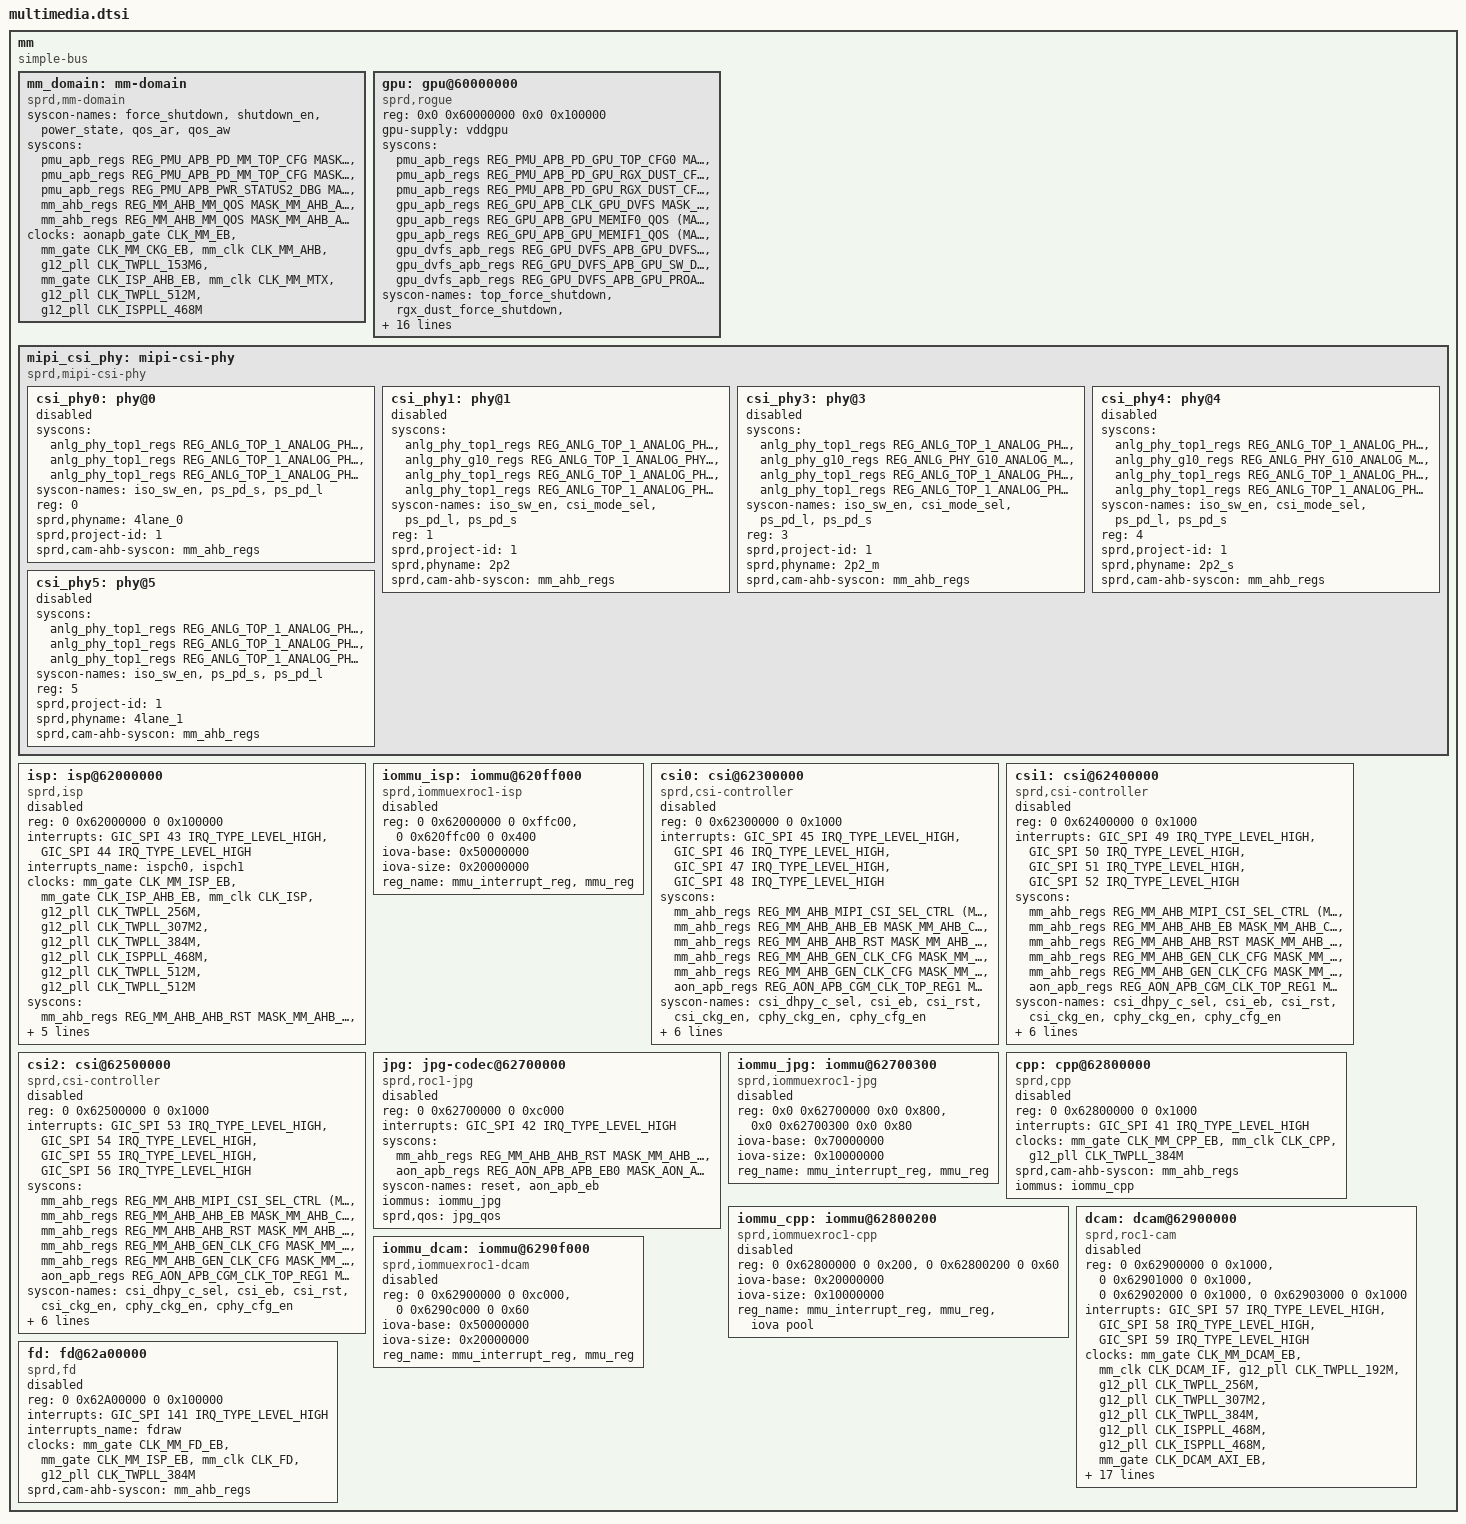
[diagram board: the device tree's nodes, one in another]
/*
 * Spreadtrum Roc1 platform DTS file
 *
 * Copyright (C) 2018, Spreadtrum Communications Inc.
 *
 * This file is licensed under a dual GPLv2 or X11 license.
 */

		mm {
			compatible = "simple-bus";
			#address-cells = <2>;
			#size-cells = <2>;
			ranges;

			mm_domain: mm-domain {
				compatible = "sprd,mm-domain";
				syscon-names = "force_shutdown",
					"shutdown_en",
					"power_state",
					"qos_ar",
					"qos_aw";
				syscons = <&pmu_apb_regs
						REG_PMU_APB_PD_MM_TOP_CFG
						MASK_PMU_APB_PD_MM_TOP_FORCE_SHUTDOWN>,
					<&pmu_apb_regs REG_PMU_APB_PD_MM_TOP_CFG
						MASK_PMU_APB_PD_MM_TOP_AUTO_SHUTDOWN_EN>,
					<&pmu_apb_regs REG_PMU_APB_PWR_STATUS2_DBG
						MASK_PMU_APB_PD_MM_TOP_STATE>,
					<&mm_ahb_regs REG_MM_AHB_MM_QOS
						MASK_MM_AHB_AR_QOS_THRESHOLD_MM>,
					<&mm_ahb_regs REG_MM_AHB_MM_QOS
						MASK_MM_AHB_AW_QOS_THRESHOLD_MM>;
				clock-names = "mm_eb",
					"mm_ahb_eb",
					"clk_mm_ahb",
					"clk_mm_ahb_parent",
					"mm_mtx_eb",
					"clk_mm_mtx",
					"clk_mm_mtx_parent",
					"clk_isppll";
				clocks = <&aonapb_gate CLK_MM_EB>,
					<&mm_gate CLK_MM_CKG_EB>,
					<&mm_clk CLK_MM_AHB>,
					<&g12_pll CLK_TWPLL_153M6>,
					<&mm_gate CLK_ISP_AHB_EB>,
					<&mm_clk CLK_MM_MTX>,
					<&g12_pll CLK_TWPLL_512M>,
					<&g12_pll CLK_ISPPLL_468M>;
				/*mm_qos_threshold = <&mm_qos_threshold>;*/
			};

			gpu: gpu@60000000 {
				compatible = "sprd,rogue";
				reg = <0x0 0x60000000 0x0 0x100000>;
				gpu-supply = <&vddgpu>;
				syscons = <&pmu_apb_regs
					REG_PMU_APB_PD_GPU_TOP_CFG0
					MASK_PMU_APB_PD_GPU_TOP_FORCE_SHUTDOWN>,
				<&pmu_apb_regs
					REG_PMU_APB_PD_GPU_RGX_DUST_CFG0
					MASK_PMU_APB_PD_GPU_RGX_DUST_FORCE_SHUTDOWN>,
				<&pmu_apb_regs
					REG_PMU_APB_PD_GPU_RGX_DUST_CFG0
					MASK_PMU_APB_PD_GPU_RGX_DUST_AUTO_SHUTDOWN_EN>,
				<&gpu_apb_regs
					REG_GPU_APB_CLK_GPU_DVFS
					MASK_GPU_APB_CGM_GPU_DVFS_EN>,
				<&gpu_apb_regs
					REG_GPU_APB_GPU_MEMIF0_QOS
					(MASK_GPU_APB_GPU_QOS_SEL0 |
					MASK_GPU_APB_AWQOS_THRESHOLD_GPU0 |
					MASK_GPU_APB_ARQOS_THRESHOLD_GPU0 |
					MASK_GPU_APB_AWQOS_GPU0 |
					MASK_GPU_APB_ARQOS_GPU0)>,
				<&gpu_apb_regs
					REG_GPU_APB_GPU_MEMIF1_QOS
					(MASK_GPU_APB_GPU_QOS_SEL1 |
					MASK_GPU_APB_AWQOS_THRESHOLD_GPU1 |
					MASK_GPU_APB_ARQOS_THRESHOLD_GPU1 |
					MASK_GPU_APB_AWQOS_GPU1 |
					MASK_GPU_APB_ARQOS_GPU1)>,
				<&gpu_dvfs_apb_regs
					REG_GPU_DVFS_APB_GPU_DVFS_INDEX_CFG
					MASK_GPU_DVFS_APB_GPU_DVFS_INDEX>,
				<&gpu_dvfs_apb_regs
					REG_GPU_DVFS_APB_GPU_SW_DVFS_CTRL
					(MASK_GPU_DVFS_APB_GPU_DVFS_ACK |
					MASK_GPU_DVFS_APB_GPU_DVFS_VOLTAGE_SW |
					MASK_GPU_DVFS_APB_GPU_DVFS_REQ_SW)>,
				<&gpu_dvfs_apb_regs
					REG_GPU_DVFS_APB_GPU_PROACTIVE_DVFS_CFG
					MASK_GPU_DVFS_APB_GPU_PROACTIVE_DVFS_SEL
					>;

				syscon-names = "top_force_shutdown",
					"rgx_dust_force_shutdown",
					"rgx_dust_auto_shutdown",
					"cgm_gpu_dvfs_en",
					"gpu0_qos",
					"gpu1_qos",
					"dvfs_index_cfg",
					"sw_dvfs_ctrl",
					"pdvfs_cfg";
				interrupts = <GIC_SPI 60 IRQ_TYPE_LEVEL_HIGH>;

				operating-points = <
					/* kHz    uV */
					384000    700000
					512000    750000
					614400    750000
					768000    800000
					800000    800000
					>;

				sprd,dvfs-lists = <
					/* kHz   uV      idx div */
					384000  700000    6    1
					512000  750000    7    1
					614400  750000    8    1
					768000  800000    9    1
					800000  800000    10   1
					>;

				sprd,dvfs-default = <0>;
				sprd,qos = <&gpu_qos>;
				sprd,dvfs-scene-extreme = <2>;
				sprd,dvfs-scene-high = <1>;
				sprd,dvfs-scene-medium = <1>;
				sprd,dvfs-scene-low = <0>;
				sprd,dvfs-range-max = <2>;
				sprd,dvfs-range-min = <0>;
			};

			mipi_csi_phy: mipi-csi-phy {
				compatible = "sprd,mipi-csi-phy";
				#address-cells = <1>;
				#size-cells = <0>;
				ranges;

				csi_phy0: phy@0 {
					syscons = <&anlg_phy_top1_regs
							REG_ANLG_TOP_1_ANALOG_PHY_POWER_DOWN_CTRL1
							MASK_ANLG_TOP_1_R2G_CSI_4LANE_0_ISO_SW_EN>,
						<&anlg_phy_top1_regs
							REG_ANLG_TOP_1_ANALOG_PHY_POWER_DOWN_CTRL1
							MASK_ANLG_TOP_1_R2G_ANALOG_MIPI_CSI_4LANE_0_CSI_PS_PD_S>,
						<&anlg_phy_top1_regs
							REG_ANLG_TOP_1_ANALOG_PHY_POWER_DOWN_CTRL1
							MASK_ANLG_TOP_1_R2G_ANALOG_MIPI_CSI_4LANE_0_CSI_PS_PD_L>;
					syscon-names = "iso_sw_en", "ps_pd_s", "ps_pd_l";
					reg = <0>;
					sprd,phyname = "4lane_0";
					sprd,project-id = <1>;
					sprd,cam-ahb-syscon = <&mm_ahb_regs>;
					status = "disabled";
				};

				csi_phy1: phy@1 {
					syscons = <&anlg_phy_top1_regs
							REG_ANLG_TOP_1_ANALOG_PHY_POWER_DOWN_CTRL1
							MASK_ANLG_TOP_1_R2G_CSI_2P2LANE_ISO_SW_EN>,
						<&anlg_phy_g10_regs
							REG_ANLG_TOP_1_ANALOG_PHY_POWER_DOWN_CTRL1
							MASK_ANLG_PHY_G10_ANALOG_MIPI_CSI_2P2LANE_CSI_MODE_SEL>,
						<&anlg_phy_top1_regs
							REG_ANLG_TOP_1_ANALOG_PHY_POWER_DOWN_CTRL1
							MASK_ANLG_TOP_1_R2G_ANALOG_MIPI_CSI_2P2LANE_CSI_PS_PD_L>,
						<&anlg_phy_top1_regs
							REG_ANLG_TOP_1_ANALOG_PHY_POWER_DOWN_CTRL1
							MASK_ANLG_TOP_1_R2G_ANALOG_MIPI_CSI_2P2LANE_CSI_PS_PD_S>;
					syscon-names = "iso_sw_en", "csi_mode_sel",
							"ps_pd_l","ps_pd_s";
					reg = <1>;
					sprd,project-id = <1>;
					sprd,phyname = "2p2";
					sprd,cam-ahb-syscon = <&mm_ahb_regs>;
					status = "disabled";
				};

				csi_phy3: phy@3 {
					syscons = <&anlg_phy_top1_regs
							REG_ANLG_TOP_1_ANALOG_PHY_POWER_DOWN_CTRL1
							MASK_ANLG_TOP_1_R2G_CSI_2P2LANE_ISO_SW_EN>,
						<&anlg_phy_g10_regs
							REG_ANLG_PHY_G10_ANALOG_MIPI_CSI_2P2LANE_CTRL_CSI_2P2L
							MASK_ANLG_PHY_G10_ANALOG_MIPI_CSI_2P2LANE_CSI_MODE_SEL>,
						<&anlg_phy_top1_regs
							REG_ANLG_TOP_1_ANALOG_PHY_POWER_DOWN_CTRL1
							MASK_ANLG_TOP_1_R2G_ANALOG_MIPI_CSI_2P2LANE_CSI_PS_PD_L>,
						<&anlg_phy_top1_regs
							REG_ANLG_TOP_1_ANALOG_PHY_POWER_DOWN_CTRL1
							MASK_ANLG_TOP_1_R2G_ANALOG_MIPI_CSI_2P2LANE_CSI_PS_PD_S>;
					syscon-names = "iso_sw_en", "csi_mode_sel",
							"ps_pd_l","ps_pd_s";
					reg = <3>;
					sprd,project-id = <1>;
					sprd,phyname = "2p2_m";
					sprd,cam-ahb-syscon = <&mm_ahb_regs>;
					status = "disabled";
				};

				csi_phy4: phy@4 {
					syscons = <&anlg_phy_top1_regs
							REG_ANLG_TOP_1_ANALOG_PHY_POWER_DOWN_CTRL1
							MASK_ANLG_TOP_1_R2G_CSI_2P2LANE_ISO_SW_EN>,
						<&anlg_phy_g10_regs
							REG_ANLG_PHY_G10_ANALOG_MIPI_CSI_2P2LANE_CTRL_CSI_2P2L
							MASK_ANLG_PHY_G10_ANALOG_MIPI_CSI_2P2LANE_CSI_MODE_SEL>,
						<&anlg_phy_top1_regs
							REG_ANLG_TOP_1_ANALOG_PHY_POWER_DOWN_CTRL1
							MASK_ANLG_TOP_1_R2G_ANALOG_MIPI_CSI_2P2LANE_CSI_PS_PD_L>,
						<&anlg_phy_top1_regs
							REG_ANLG_TOP_1_ANALOG_PHY_POWER_DOWN_CTRL1
							MASK_ANLG_TOP_1_R2G_ANALOG_MIPI_CSI_2P2LANE_CSI_PS_PD_S>;
					syscon-names = "iso_sw_en", "csi_mode_sel",
							"ps_pd_l", "ps_pd_s";
					reg = <4>;
					sprd,project-id = <1>;
					sprd,phyname = "2p2_s";
					sprd,cam-ahb-syscon = <&mm_ahb_regs>;
					status = "disabled";
				};

				csi_phy5: phy@5 {
					syscons = <&anlg_phy_top1_regs
							REG_ANLG_TOP_1_ANALOG_PHY_POWER_DOWN_CTRL1
							MASK_ANLG_TOP_1_R2G_CSI_4LANE_1_ISO_SW_EN>,
						<&anlg_phy_top1_regs
							REG_ANLG_TOP_1_ANALOG_PHY_POWER_DOWN_CTRL1
							MASK_ANLG_TOP_1_R2G_ANALOG_MIPI_CSI_4LANE_1_CSI_PS_PD_S>,
						<&anlg_phy_top1_regs
							REG_ANLG_TOP_1_ANALOG_PHY_POWER_DOWN_CTRL1
							MASK_ANLG_TOP_1_R2G_ANALOG_MIPI_CSI_4LANE_1_CSI_PS_PD_L>;
					syscon-names = "iso_sw_en", "ps_pd_s", "ps_pd_l";
					reg = <5>;
					sprd,project-id = <1>;
					sprd,phyname = "4lane_1";
					sprd,cam-ahb-syscon = <&mm_ahb_regs>;
					status = "disabled";
				};
			};

			isp: isp@62000000 {
				compatible = "sprd,isp";
				reg = <0 0x62000000 0 0x100000>;
				interrupts = <GIC_SPI 43 IRQ_TYPE_LEVEL_HIGH>,
					<GIC_SPI 44 IRQ_TYPE_LEVEL_HIGH>;
				interrupts_name = "ispch0", "ispch1";
				clock-names = "isp_eb",
					"isp_axi_eb",
					"isp_clk",
					"isp_clk_256m",
					"isp_clk_307m2",
					"isp_clk_384m",
					"isp_clk_468m",
					"isp_clk_512m",
					"isp_clk_parent";
				clocks = <&mm_gate CLK_MM_ISP_EB>,
					<&mm_gate CLK_ISP_AHB_EB>,
					<&mm_clk CLK_ISP>,
					<&g12_pll CLK_TWPLL_256M>,
					<&g12_pll CLK_TWPLL_307M2>,
					<&g12_pll CLK_TWPLL_384M>,
					<&g12_pll CLK_ISPPLL_468M>,
					<&g12_pll CLK_TWPLL_512M>,
					<&g12_pll CLK_TWPLL_512M>;
				syscons = <&mm_ahb_regs REG_MM_AHB_AHB_RST
					MASK_MM_AHB_ISP_SOFT_RST>,
					<&mm_ahb_regs REG_MM_AHB_AHB_RST
					MASK_MM_AHB_ISP_AHB_SOFT_RST>;
				syscon-names = "reset",
						"isp_ahb_reset";
				sprd,cam-ahb-syscon = <&mm_ahb_regs>;
				sprd,isp-count = <1>;
				iommus = <&iommu_isp>;
				/*isp_qos = <&isp_qos>;*/
				status = "disabled";
			};

			iommu_isp: iommu@620ff000 {
				compatible = "sprd,iommuexroc1-isp";
				reg = <0 0x62000000 0 0xffc00>,
				      <0 0x620ffc00 0 0x400>;
				iova-base = <0x50000000>;
				iova-size = <0x20000000>;
				reg_name = "mmu_interrupt_reg","mmu_reg";
				status = "disabled";
				#iommu-cells = <0>;
			};

			csi0: csi@62300000 {
				compatible = "sprd,csi-controller";
				reg = <0 0x62300000 0 0x1000>;
				interrupts = <GIC_SPI 45 IRQ_TYPE_LEVEL_HIGH>,
					<GIC_SPI 46 IRQ_TYPE_LEVEL_HIGH>,
					<GIC_SPI 47 IRQ_TYPE_LEVEL_HIGH>,
					<GIC_SPI 48 IRQ_TYPE_LEVEL_HIGH>;
				syscons = <&mm_ahb_regs
						REG_MM_AHB_MIPI_CSI_SEL_CTRL
						(MASK_MM_AHB_MIPI_CSI_DPHY_C0_SEL0 |
						MASK_MM_AHB_MIPI_CSI_DPHY_C0_SEL1)>,
					<&mm_ahb_regs REG_MM_AHB_AHB_EB
						MASK_MM_AHB_CSI0_EB>,
					<&mm_ahb_regs REG_MM_AHB_AHB_RST
						MASK_MM_AHB_MIPI_CSI0_SOFT_RST>,
					<&mm_ahb_regs REG_MM_AHB_GEN_CLK_CFG
						MASK_MM_AHB_MIPI_CSI0_CKG_EN>,
					<&mm_ahb_regs REG_MM_AHB_GEN_CLK_CFG
						MASK_MM_AHB_CPHY_CFG_CKG_EN>,
					<&aon_apb_regs REG_AON_APB_CGM_CLK_TOP_REG1
						MASK_AON_APB_CGM_CPHY_CFG_EN>;
				syscon-names = "csi_dhpy_c_sel",
					"csi_eb",
					"csi_rst",
					"csi_ckg_en",
					"cphy_ckg_en",
					"cphy_cfg_en";
				clock-names = "csi_eb",
					"mipi_csi_eb",
					"mipi_csi_src";
				clocks = <&mm_gate CLK_MM_CSI0_EB>,
				       <&mm_gate CLK_MM_MIPI_CSI0_EB>,
				       <&mm_clk CLK_MIPI_CSI0>;
				sprd,csi-id = <0>;
				sprd,dcam-id = <0>;
				sprd,ip-version = <0x200>;
				status = "disable";
			};
			csi1: csi@62400000 {
				compatible = "sprd,csi-controller";
				reg = <0 0x62400000 0 0x1000>;
				interrupts = <GIC_SPI 49 IRQ_TYPE_LEVEL_HIGH>,
					<GIC_SPI 50 IRQ_TYPE_LEVEL_HIGH>,
					<GIC_SPI 51 IRQ_TYPE_LEVEL_HIGH>,
					<GIC_SPI 52 IRQ_TYPE_LEVEL_HIGH>;
				syscons = <&mm_ahb_regs
						REG_MM_AHB_MIPI_CSI_SEL_CTRL
						(MASK_MM_AHB_MIPI_CSI_DPHY_C1_SEL0
						| MASK_MM_AHB_MIPI_CSI_DPHY_C1_SEL1)>,
					<&mm_ahb_regs REG_MM_AHB_AHB_EB
						MASK_MM_AHB_CSI1_EB>,
					<&mm_ahb_regs REG_MM_AHB_AHB_RST
						MASK_MM_AHB_MIPI_CSI1_SOFT_RST>,
					<&mm_ahb_regs REG_MM_AHB_GEN_CLK_CFG
						MASK_MM_AHB_MIPI_CSI1_CKG_EN>,
					<&mm_ahb_regs REG_MM_AHB_GEN_CLK_CFG
						MASK_MM_AHB_CPHY_CFG_CKG_EN>,
					<&aon_apb_regs REG_AON_APB_CGM_CLK_TOP_REG1
						MASK_AON_APB_CGM_CPHY_CFG_EN>;
				syscon-names = "csi_dhpy_c_sel",
					"csi_eb",
					"csi_rst",
					"csi_ckg_en",
					"cphy_ckg_en",
					"cphy_cfg_en";
				clock-names = "csi_eb",
					"mipi_csi_eb",
					"mipi_csi_src";
				clocks = <&mm_gate CLK_MM_CSI1_EB>,
				       <&mm_gate CLK_MM_MIPI_CSI1_EB>,
				       <&mm_clk CLK_MIPI_CSI1>;
				sprd,csi-id = <1>;
				sprd,dcam-id = <1>;
				sprd,ip-version = <0x200>;
				status = "disable";
			};
			csi2: csi@62500000 {
				compatible = "sprd,csi-controller";
				reg = <0 0x62500000 0 0x1000>;
				interrupts = <GIC_SPI 53 IRQ_TYPE_LEVEL_HIGH>,
					<GIC_SPI 54 IRQ_TYPE_LEVEL_HIGH>,
					<GIC_SPI 55 IRQ_TYPE_LEVEL_HIGH>,
					<GIC_SPI 56 IRQ_TYPE_LEVEL_HIGH>;
				syscons = <&mm_ahb_regs
						REG_MM_AHB_MIPI_CSI_SEL_CTRL
						(MASK_MM_AHB_MIPI_CSI_DPHY_C2_SEL0
						| MASK_MM_AHB_MIPI_CSI_DPHY_C2_SEL1)>,
					<&mm_ahb_regs REG_MM_AHB_AHB_EB
						MASK_MM_AHB_CSI2_EB>,
					<&mm_ahb_regs REG_MM_AHB_AHB_RST
						MASK_MM_AHB_MIPI_CSI2_SOFT_RST>,
					<&mm_ahb_regs REG_MM_AHB_GEN_CLK_CFG
						MASK_MM_AHB_MIPI_CSI2_CKG_EN>,
					<&mm_ahb_regs REG_MM_AHB_GEN_CLK_CFG
						MASK_MM_AHB_CPHY_CFG_CKG_EN>,
					<&aon_apb_regs REG_AON_APB_CGM_CLK_TOP_REG1
						MASK_AON_APB_CGM_CPHY_CFG_EN>;
				syscon-names = "csi_dhpy_c_sel",
					"csi_eb",
					"csi_rst",
					"csi_ckg_en",
					"cphy_ckg_en",
					"cphy_cfg_en";
				clock-names = "csi_eb",
					"mipi_csi_eb",
					"mipi_csi_src";
				clocks = <&mm_gate CLK_MM_CSI2_EB>,
				       <&mm_gate CLK_MM_MIPI_CSI2_EB>,
				       <&mm_clk CLK_MIPI_CSI2>;
				sprd,csi-id = <2>;
				sprd,dcam-id = <2>;
				sprd,ip-version = <0x200>;
				status = "disable";
			};

			jpg: jpg-codec@62700000{
				compatible = "sprd,roc1-jpg";
				reg = <0 0x62700000 0 0xc000>;
				interrupts = <GIC_SPI 42 IRQ_TYPE_LEVEL_HIGH>;

				syscons = <&mm_ahb_regs REG_MM_AHB_AHB_RST
						MASK_MM_AHB_JPG_SOFT_RST>,
					<&aon_apb_regs
						REG_AON_APB_APB_EB0
						MASK_AON_APB_MM_EB>;
				syscon-names = "reset",
					"aon_apb_eb";
				iommus = <&iommu_jpg>;
				sprd,qos = <&jpg_qos>;
				status = "disabled";
			};

			iommu_jpg: iommu@62700300 {
				compatible = "sprd,iommuexroc1-jpg";
				reg = <0x0 0x62700000 0x0 0x800>,
				      <0x0 0x62700300 0x0 0x80>;
				iova-base = <0x70000000>;
				iova-size = <0x10000000>;
				reg_name = "mmu_interrupt_reg","mmu_reg";
				status = "disabled";
				#iommu-cells = <0>;
			};

			cpp: cpp@62800000 {
				compatible = "sprd,cpp";
				reg = <0 0x62800000 0 0x1000>;
				interrupts = <GIC_SPI 41 IRQ_TYPE_LEVEL_HIGH>;
				clock-names = "cpp_eb",
					"cpp_clk",
					"cpp_clk_parent";
				clocks = <&mm_gate CLK_MM_CPP_EB>,
					<&mm_clk CLK_CPP>,
					<&g12_pll CLK_TWPLL_384M>;
				sprd,cam-ahb-syscon = <&mm_ahb_regs>;
				iommus = <&iommu_cpp>;
				/* cpp_qos = <&cpp_qos>; */
				status = "disabled";
			};

			iommu_cpp: iommu@62800200 {
				compatible = "sprd,iommuexroc1-cpp";
				reg = <0 0x62800000 0 0x200>,
					<0 0x62800200 0 0x60>;
				iova-base = <0x20000000>;
				iova-size = <0x10000000>;
				reg_name = "mmu_interrupt_reg","mmu_reg",
					"iova pool";
				status = "disabled";
				#iommu-cells = <0>;
			};

			dcam: dcam@62900000 {
				compatible = "sprd,roc1-cam";
				reg = <0 0x62900000 0 0x1000>,
					<0 0x62901000 0 0x1000>,
					<0 0x62902000 0 0x1000>,
					<0 0x62903000 0 0x1000>;
				reg-names = "dcam0_reg",
						 "dcam1_reg",
						 "dcam2_reg",
						 "axi_ctrl_reg";
				interrupts = <GIC_SPI 57 IRQ_TYPE_LEVEL_HIGH>,
					   <GIC_SPI 58 IRQ_TYPE_LEVEL_HIGH>,
					   <GIC_SPI 59 IRQ_TYPE_LEVEL_HIGH>;
				interrupt-names = "dcam0",
						"dcam1",
						"dcam2";
				clock-names = "dcam_eb",
					"dcam_clk",
					"dcam_clk_192m",
					"dcam_clk_256m",
					"dcam_clk_307m2",
					"dcam_clk_384m",
					"dcam_clk_468m",
					"dcam_clk_parent",
					"dcam_axi_eb",
					"dcam_axi_clk",
					"dcam_axi_clk_256m",
					"dcam_axi_clk_307m2",
					"dcam_axi_clk_384m",
					"dcam_axi_clk_468m",
					"dcam_axi_clk_parent";
				clocks = <&mm_gate CLK_MM_DCAM_EB>,
					<&mm_clk CLK_DCAM_IF>,
					<&g12_pll CLK_TWPLL_192M>,
					<&g12_pll CLK_TWPLL_256M>,
					<&g12_pll CLK_TWPLL_307M2>,
					<&g12_pll CLK_TWPLL_384M>,
					<&g12_pll CLK_ISPPLL_468M>,
					<&g12_pll CLK_ISPPLL_468M>,
					<&mm_gate CLK_DCAM_AXI_EB>,
					<&mm_clk CLK_DCAM_AXI>,
					<&g12_pll CLK_TWPLL_256M>,
					<&g12_pll CLK_TWPLL_307M2>,
					<&g12_pll CLK_TWPLL_384M>,
					<&g12_pll CLK_ISPPLL_468M>,
					<&g12_pll CLK_ISPPLL_468M>;
				syscons = <&mm_ahb_regs REG_MM_AHB_AHB_RST
					MASK_MM_AHB_DCAM_ALL_SOFT_RST>,
					<&mm_ahb_regs REG_MM_AHB_AHB_RST
					MASK_MM_AHB_DCAM0_SOFT_RST>,
					<&mm_ahb_regs REG_MM_AHB_AHB_RST
					MASK_MM_AHB_DCAM1_SOFT_RST>,
					<&mm_ahb_regs REG_MM_AHB_AHB_RST
					MASK_MM_AHB_DCAM2_SOFT_RST>;
				syscon-names = "dcam_all_reset",
						"dcam0_reset",
						"dcam1_reset",
						"dcam2_reset";
				sprd,cam-ahb-syscon = <&mm_ahb_regs>;
				sprd,isp = <&isp>;
				sprd,dcam-count = <3>;
				sprd,project-id = <2>;
				iommus = <&iommu_dcam>;
				/*dcam_qos = <&dcam_qos>;*/
				status = "disabled";
			};

			iommu_dcam: iommu@6290f000 {
				compatible = "sprd,iommuexroc1-dcam";
				reg = <0 0x62900000 0 0xc000>,
				      <0 0x6290c000 0 0x60>;
				iova-base = <0x50000000>;
				iova-size = <0x20000000>;
				reg_name = "mmu_interrupt_reg", "mmu_reg";
				status = "disabled";
				#iommu-cells = <0>;
			};

			fd: fd@62a00000 {
				compatible = "sprd,fd";
				reg = <0 0x62A00000 0 0x100000>;
				interrupts = <GIC_SPI 141 IRQ_TYPE_LEVEL_HIGH>;
				interrupts_name = "fdraw";
				clock-names = "fd_eb",
					"fd_axi_eb",
					"fd_clk",
					"fd_clk_parent";
				clocks = <&mm_gate CLK_MM_FD_EB>,
					<&mm_gate CLK_MM_ISP_EB>,
					<&mm_clk CLK_FD>,
					<&g12_pll CLK_TWPLL_384M>;
				sprd,cam-ahb-syscon = <&mm_ahb_regs>;
				/*iommus = <&iommu_fd>;*/
				/*fd_qos = <&fd_qos>;*/
				status = "disabled";
			};

		};

